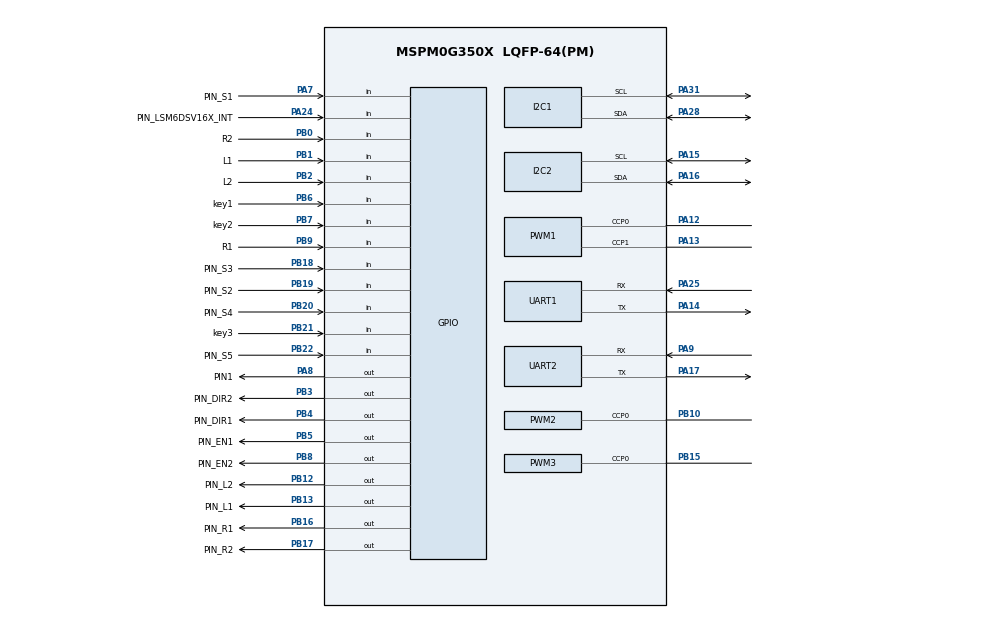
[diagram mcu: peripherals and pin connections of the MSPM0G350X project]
/**
 * @cliArgs --device "MSPM0G350X" --part "Default" --package "LQFP-64(PM)" --product "mspm0_sdk@2.05.00.05"
 * @versions {"tool":"1.24.0+4110"}
 */

/**
 * Import the modules used in this configuration.
 */
const GPIO   = scripting.addModule("/ti/driverlib/GPIO", {}, false);
const GPIO1  = GPIO.addInstance();
const GPIO2  = GPIO.addInstance();
const GPIO3  = GPIO.addInstance();
const GPIO4  = GPIO.addInstance();
const GPIO5  = GPIO.addInstance();
const GPIO6  = GPIO.addInstance();
const GPIO7  = GPIO.addInstance();
const GPIO8  = GPIO.addInstance();
const I2C    = scripting.addModule("/ti/driverlib/I2C", {}, false);
const I2C1   = I2C.addInstance();
const I2C2   = I2C.addInstance();
const PWM    = scripting.addModule("/ti/driverlib/PWM", {}, false);
const PWM1   = PWM.addInstance();
const PWM2   = PWM.addInstance();
const PWM3   = PWM.addInstance();
const SYSCTL = scripting.addModule("/ti/driverlib/SYSCTL");
const TIMER  = scripting.addModule("/ti/driverlib/TIMER", {}, false);
const TIMER1 = TIMER.addInstance();
const UART   = scripting.addModule("/ti/driverlib/UART", {}, false);
const UART1  = UART.addInstance();
const UART2  = UART.addInstance();

/**
 * Write custom configuration values to the imported modules.
 */
const divider6       = system.clockTree["PLL_CLK2X_DIV"];
divider6.divideValue = 4;

const divider7       = system.clockTree["PLL_PDIV"];
divider7.divideValue = 2;

const divider9       = system.clockTree["UDIV"];
divider9.divideValue = 2;

const multiplier2         = system.clockTree["PLL_QDIV"];
multiplier2.multiplyValue = 10;

const mux8       = system.clockTree["HSCLKMUX"];
mux8.inputSelect = "HSCLKMUX_SYSPLL2X";

GPIO1.$name                         = "GPIO_GRP_Motor";
GPIO1.associatedPins.create(4);
GPIO1.associatedPins[0].$name       = "PIN_L1";
GPIO1.associatedPins[0].pin.$assign = "PB13";
GPIO1.associatedPins[1].$name       = "PIN_L2";
GPIO1.associatedPins[1].pin.$assign = "PB12";
GPIO1.associatedPins[2].$name       = "PIN_R1";
GPIO1.associatedPins[2].pin.$assign = "PB16";
GPIO1.associatedPins[3].$name       = "PIN_R2";
GPIO1.associatedPins[3].pin.$assign = "PB17";

const Board = scripting.addModule("/ti/driverlib/Board", {}, false);

GPIO2.$name                         = "GPIO_Encoder";
GPIO2.associatedPins.create(4);
GPIO2.associatedPins[0].direction   = "INPUT";
GPIO2.associatedPins[0].interruptEn = true;
GPIO2.associatedPins[0].polarity    = "RISE";
GPIO2.associatedPins[0].$name       = "R1";
GPIO2.associatedPins[0].pin.$assign = "PB9";
GPIO2.associatedPins[1].direction   = "INPUT";
GPIO2.associatedPins[1].$name       = "R2";
GPIO2.associatedPins[1].pin.$assign = "PB0";
GPIO2.associatedPins[2].direction   = "INPUT";
GPIO2.associatedPins[2].interruptEn = true;
GPIO2.associatedPins[2].polarity    = "RISE";
GPIO2.associatedPins[2].$name       = "L1";
GPIO2.associatedPins[2].pin.$assign = "PB1";
GPIO2.associatedPins[3].direction   = "INPUT";
GPIO2.associatedPins[3].interruptEn = true;
GPIO2.associatedPins[3].polarity    = "RISE";
GPIO2.associatedPins[3].$name       = "L2";
GPIO2.associatedPins[3].pin.$assign = "PB2";

GPIO3.$name                          = "GPIO_GRP_EN";
GPIO3.associatedPins.create(2);
GPIO3.associatedPins[0].$name        = "PIN_EN1";
GPIO3.associatedPins[0].initialValue = "SET";
GPIO3.associatedPins[0].pin.$assign  = "PB5";
GPIO3.associatedPins[1].$name        = "PIN_EN2";
GPIO3.associatedPins[1].initialValue = "SET";
GPIO3.associatedPins[1].pin.$assign  = "PB8";

GPIO4.$name                         = "GPIO_GRP_DIR";
GPIO4.associatedPins.create(2);
GPIO4.associatedPins[0].$name       = "PIN_DIR1";
GPIO4.associatedPins[0].pin.$assign = "PB4";
GPIO4.associatedPins[1].$name       = "PIN_DIR2";
GPIO4.associatedPins[1].pin.$assign = "PB3";

GPIO5.$name                         = "GPIO_GRP_XUN";
GPIO5.associatedPins.create(5);
GPIO5.associatedPins[0].$name       = "PIN_S1";
GPIO5.associatedPins[0].direction   = "INPUT";
GPIO5.associatedPins[0].pin.$assign = "PA7";
GPIO5.associatedPins[1].$name       = "PIN_S2";
GPIO5.associatedPins[1].direction   = "INPUT";
GPIO5.associatedPins[1].pin.$assign = "PB19";
GPIO5.associatedPins[2].$name       = "PIN_S3";
GPIO5.associatedPins[2].direction   = "INPUT";
GPIO5.associatedPins[2].pin.$assign = "PB18";
GPIO5.associatedPins[3].$name       = "PIN_S4";
GPIO5.associatedPins[3].direction   = "INPUT";
GPIO5.associatedPins[3].pin.$assign = "PB20";
GPIO5.associatedPins[4].$name       = "PIN_S5";
GPIO5.associatedPins[4].direction   = "INPUT";
GPIO5.associatedPins[4].pin.$assign = "PB22";

GPIO6.$name                          = "GPIO_GRP_relay";
GPIO6.associatedPins[0].$name        = "PIN1";
GPIO6.associatedPins[0].initialValue = "SET";
GPIO6.associatedPins[0].pin.$assign  = "PA8";

GPIO7.$name                              = "GPIO_GRP_Key";
GPIO7.associatedPins.create(3);
GPIO7.associatedPins[0].direction        = "INPUT";
GPIO7.associatedPins[0].internalResistor = "PULL_UP";
GPIO7.associatedPins[0].$name            = "key1";
GPIO7.associatedPins[0].pin.$assign      = "PB6";
GPIO7.associatedPins[1].direction        = "INPUT";
GPIO7.associatedPins[1].internalResistor = "PULL_UP";
GPIO7.associatedPins[1].$name            = "key2";
GPIO7.associatedPins[1].pin.$assign      = "PB7";
GPIO7.associatedPins[2].direction        = "INPUT";
GPIO7.associatedPins[2].internalResistor = "PULL_UP";
GPIO7.associatedPins[2].$name            = "key3";
GPIO7.associatedPins[2].pin.$assign      = "PB21";

GPIO8.$name                               = "GPIO_LSM6DSV16X";
GPIO8.associatedPins[0].$name             = "PIN_LSM6DSV16X_INT";
GPIO8.associatedPins[0].direction         = "INPUT";
GPIO8.associatedPins[0].interruptEn       = true;
GPIO8.associatedPins[0].interruptPriority = "3";
GPIO8.associatedPins[0].polarity          = "RISE";
GPIO8.associatedPins[0].pin.$assign       = "PA24";

I2C1.$name                             = "I2C_OLED";
I2C1.basicEnableController             = true;
I2C1.basicControllerStandardBusSpeed   = "Fast";
I2C1.peripheral.sdaPin.$assign         = "PA28";
I2C1.peripheral.sclPin.$assign         = "PA31";
I2C1.sdaPinConfig.hideOutputInversion  = scripting.forceWrite(false);
I2C1.sdaPinConfig.onlyInternalResistor = scripting.forceWrite(false);
I2C1.sdaPinConfig.passedPeripheralType = scripting.forceWrite("Digital");
I2C1.sdaPinConfig.$name                = "ti_driverlib_gpio_GPIOPinGeneric2";
I2C1.sclPinConfig.hideOutputInversion  = scripting.forceWrite(false);
I2C1.sclPinConfig.onlyInternalResistor = scripting.forceWrite(false);
I2C1.sclPinConfig.passedPeripheralType = scripting.forceWrite("Digital");
I2C1.sclPinConfig.$name                = "ti_driverlib_gpio_GPIOPinGeneric3";

I2C2.basicEnableController             = true;
I2C2.advControllerTXFIFOTRIG           = "BYTES_7";
I2C2.advControllerRXFIFOTRIG           = "BYTES_8";
I2C2.$name                             = "I2C_LSM6DSV16X";
I2C2.basicControllerStandardBusSpeed   = "FastPlus";
I2C2.peripheral.sdaPin.$assign         = "PA16";
I2C2.peripheral.sclPin.$assign         = "PA15";
I2C2.sdaPinConfig.hideOutputInversion  = scripting.forceWrite(false);
I2C2.sdaPinConfig.onlyInternalResistor = scripting.forceWrite(false);
I2C2.sdaPinConfig.passedPeripheralType = scripting.forceWrite("Digital");
I2C2.sdaPinConfig.$name                = "ti_driverlib_gpio_GPIOPinGeneric4";
I2C2.sclPinConfig.hideOutputInversion  = scripting.forceWrite(false);
I2C2.sclPinConfig.onlyInternalResistor = scripting.forceWrite(false);
I2C2.sclPinConfig.passedPeripheralType = scripting.forceWrite("Digital");
I2C2.sclPinConfig.$name                = "ti_driverlib_gpio_GPIOPinGeneric5";

PWM1.pwmMode                            = "EDGE_ALIGN_UP";
PWM1.timerStartTimer                    = true;
PWM1.$name                              = "PWM_Front";
PWM1.timerCount                         = 4000;
PWM1.peripheral.$assign                 = "TIMG0";
PWM1.peripheral.ccp0Pin.$assign         = "PA12";
PWM1.peripheral.ccp1Pin.$assign         = "PA13";
PWM1.PWM_CHANNEL_0.$name                = "ti_driverlib_pwm_PWMTimerCC0";
PWM1.PWM_CHANNEL_1.$name                = "ti_driverlib_pwm_PWMTimerCC1";
PWM1.ccp0PinConfig.direction            = scripting.forceWrite("OUTPUT");
PWM1.ccp0PinConfig.hideOutputInversion  = scripting.forceWrite(false);
PWM1.ccp0PinConfig.onlyInternalResistor = scripting.forceWrite(false);
PWM1.ccp0PinConfig.passedPeripheralType = scripting.forceWrite("Digital");
PWM1.ccp0PinConfig.$name                = "ti_driverlib_gpio_GPIOPinGeneric0";
PWM1.ccp1PinConfig.direction            = scripting.forceWrite("OUTPUT");
PWM1.ccp1PinConfig.hideOutputInversion  = scripting.forceWrite(false);
PWM1.ccp1PinConfig.onlyInternalResistor = scripting.forceWrite(false);
PWM1.ccp1PinConfig.passedPeripheralType = scripting.forceWrite("Digital");
PWM1.ccp1PinConfig.$name                = "ti_driverlib_gpio_GPIOPinGeneric1";

PWM2.$name                              = "PWM_X";
PWM2.ccIndex                            = [0];
PWM2.interrupts                         = ["ZERO_EVENT"];
PWM2.clockDivider                       = 8;
PWM2.timerCount                         = 625;
PWM2.PWM_CHANNEL_0.$name                = "ti_driverlib_pwm_PWMTimerCC2";
PWM2.PWM_CHANNEL_0.dutyCycle            = 50;
PWM2.ccp0PinConfig.direction            = scripting.forceWrite("OUTPUT");
PWM2.ccp0PinConfig.hideOutputInversion  = scripting.forceWrite(false);
PWM2.ccp0PinConfig.onlyInternalResistor = scripting.forceWrite(false);
PWM2.ccp0PinConfig.passedPeripheralType = scripting.forceWrite("Digital");
PWM2.ccp0PinConfig.$name                = "ti_driverlib_gpio_GPIOPinGeneric8";
PWM2.peripheral.$assign                 = "TIMG6";
PWM2.peripheral.ccp0Pin.$assign         = "PB10";

PWM3.$name                              = "PWM_Y";
PWM3.ccIndex                            = [0];
PWM3.interrupts                         = ["ZERO_EVENT"];
PWM3.clockDivider                       = 8;
PWM3.timerCount                         = 625;
PWM3.PWM_CHANNEL_0.$name                = "ti_driverlib_pwm_PWMTimerCC4";
PWM3.PWM_CHANNEL_0.dutyCycle            = 50;
PWM3.ccp0PinConfig.direction            = scripting.forceWrite("OUTPUT");
PWM3.ccp0PinConfig.hideOutputInversion  = scripting.forceWrite(false);
PWM3.ccp0PinConfig.onlyInternalResistor = scripting.forceWrite(false);
PWM3.ccp0PinConfig.passedPeripheralType = scripting.forceWrite("Digital");
PWM3.ccp0PinConfig.$name                = "ti_driverlib_gpio_GPIOPinGeneric10";
PWM3.peripheral.$assign                 = "TIMG7";
PWM3.peripheral.ccp0Pin.$assign         = "PB15";

SYSCTL.forceDefaultClkConfig = true;
SYSCTL.clockTreeEn           = true;

TIMER1.$name       = "TIMER_0";
TIMER1.timerMode   = "PERIODIC";
TIMER1.timerClkDiv = 8;
TIMER1.timerClkSrc = "LFCLK";
TIMER1.interrupts  = ["ZERO"];
TIMER1.timerPeriod = "20ms";

UART1.$name                             = "UART_WIT";
UART1.targetBaudRate                    = 115200;
UART1.enableFIFO                        = true;
UART1.rxTimeoutValue                    = 1;
UART1.enabledInterrupts                 = ["RX_TIMEOUT_ERROR"];
UART1.enabledDMARXTriggers              = "DL_UART_DMA_INTERRUPT_RX";
UART1.peripheral.rxPin.$assign          = "PA25";
UART1.peripheral.txPin.$assign          = "PA14";
UART1.txPinConfig.direction             = scripting.forceWrite("OUTPUT");
UART1.txPinConfig.hideOutputInversion   = scripting.forceWrite(false);
UART1.txPinConfig.onlyInternalResistor  = scripting.forceWrite(false);
UART1.txPinConfig.passedPeripheralType  = scripting.forceWrite("Digital");
UART1.txPinConfig.$name                 = "ti_driverlib_gpio_GPIOPinGeneric6";
UART1.rxPinConfig.hideOutputInversion   = scripting.forceWrite(false);
UART1.rxPinConfig.onlyInternalResistor  = scripting.forceWrite(false);
UART1.rxPinConfig.passedPeripheralType  = scripting.forceWrite("Digital");
UART1.rxPinConfig.$name                 = "ti_driverlib_gpio_GPIOPinGeneric7";
UART1.DMA_CHANNEL_RX.$name              = "DMA_WIT";
UART1.DMA_CHANNEL_RX.addressMode        = "f2b";
UART1.DMA_CHANNEL_RX.srcLength          = "BYTE";
UART1.DMA_CHANNEL_RX.dstLength          = "BYTE";
UART1.DMA_CHANNEL_RX.peripheral.$assign = "DMA_CH2";

UART2.$name                            = "UART_Camera";
UART2.targetBaudRate                   = 115200;
UART2.enabledInterrupts                = ["RX"];
UART2.interruptPriority                = "1";
UART2.peripheral.$assign               = "UART1";
UART2.peripheral.rxPin.$assign         = "PA9";
UART2.peripheral.txPin.$assign         = "PA17";
UART2.txPinConfig.direction            = scripting.forceWrite("OUTPUT");
UART2.txPinConfig.hideOutputInversion  = scripting.forceWrite(false);
UART2.txPinConfig.onlyInternalResistor = scripting.forceWrite(false);
UART2.txPinConfig.passedPeripheralType = scripting.forceWrite("Digital");
UART2.txPinConfig.$name                = "ti_driverlib_gpio_GPIOPinGeneric9";
UART2.rxPinConfig.hideOutputInversion  = scripting.forceWrite(false);
UART2.rxPinConfig.onlyInternalResistor = scripting.forceWrite(false);
UART2.rxPinConfig.passedPeripheralType = scripting.forceWrite("Digital");
UART2.rxPinConfig.$name                = "ti_driverlib_gpio_GPIOPinGeneric11";

/**
 * Pinmux solution for unlocked pins/peripherals. This ensures that minor changes to the automatic solver in a future
 * version of the tool will not impact the pinmux you originally saw.  These lines can be completely deleted in order to
 * re-solve from scratch.
 */
Board.peripheral.$suggestSolution          = "DEBUGSS";
Board.peripheral.swclkPin.$suggestSolution = "PA20";
Board.peripheral.swdioPin.$suggestSolution = "PA19";
I2C1.peripheral.$suggestSolution           = "I2C0";
I2C2.peripheral.$suggestSolution           = "I2C1";
TIMER1.peripheral.$suggestSolution         = "TIMA0";
UART1.peripheral.$suggestSolution          = "UART3";
